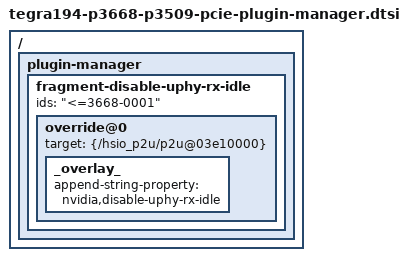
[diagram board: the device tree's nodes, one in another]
/*
 * Copyright (c) 2019, NVIDIA CORPORATION.  All rights reserved.
 *
 * This program is free software; you can redistribute it and/or modify
 * it under the terms of the GNU General Public License as published by
 * the Free Software Foundation; either version 2 of the License, or
 * (at your option) any later version.
 *
 * This program is distributed in the hope that it will be useful, but WITHOUT
 * ANY WARRANTY; without even the implied warranty of MERCHANTABILITY or
 * FITNESS FOR A PARTICULAR PURPOSE.  See the GNU General Public License for
 * more details.
 */

/ {
	plugin-manager {
		fragment-disable-uphy-rx-idle {
			ids = "<=3668-0001";
			override@0 {
				target = <&{/hsio_p2u/p2u@03e10000}>;
				_overlay_ {
					append-string-property = "nvidia,disable-uphy-rx-idle";
				};
			};
		};
	};
};
